# netx90_app register map
File version: 1.0
CPU: CM4 r0p1, little endian, MPU, FPU, 4 interrupt priority bits, 78 interrupts
Registers are 32-bit, read-write, reset 0x0 unless marked. A register's access mark holds for its fields unless they carry their own. Offsets are from the block's base; [hi:lo] are bit positions; {n}, {i} and the like mark numbered series; 'fields as' and 'values as' point back to an identical list.

## timer_app
Base 0xFF801600
Same registers: timer_xpic_app 0xFF900100
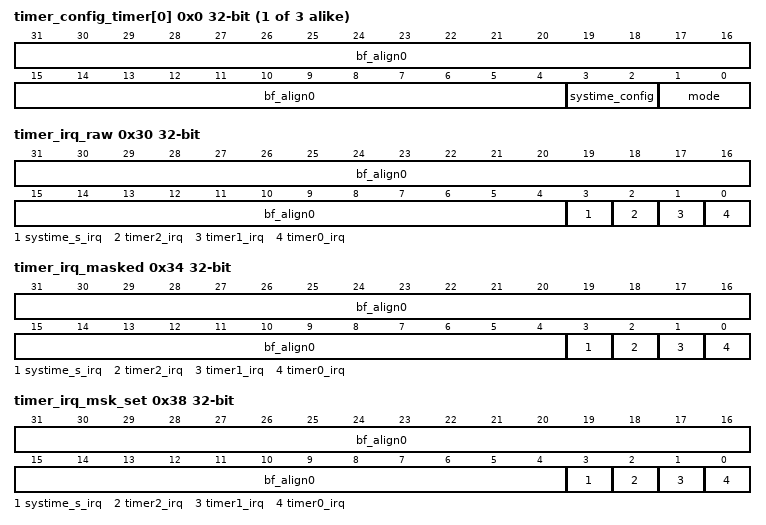
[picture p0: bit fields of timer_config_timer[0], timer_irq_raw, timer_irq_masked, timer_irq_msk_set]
{0x0+4i} timer_config_timer[{i}] (i=0..2) (reset mask 0xF) — ARM TIMER Config register0
  [31:4] bf_align0 — bitField alignment value for aeabi compatibility
  [3:2] systime_config — systime for timer (2'b00.. systime_com, 2'b01.. systime_com_uc, 2'b10.. systime_app)
  [1:0] mode — Timer0 2'b00 : Timer stops at 0 2'b01 : Timer is preload with value from preload register at 0 2'b10 : Timer (value) compare with systime (once) 2'b11 : reserved
{0xC+4i} timer_preload_timer[{i}] (i=0..2) — ARM TIMER Timer 0
  [31:0] val — preload value
{0x18+4i} timer_timer[{i}] (i=0..2) — ARM TIMER Timer 0
  [31:0] val — actual value of timer / systime compare value
0x24 timer_systime_s ro — ARM_TIMER upper SYSTIME register To allow consistent values of systime_s and systime_ns, lower bits of systime is latched to systime_ns, when systime_s is read. This register should be dedicated to accesses via ARM. xPIC software should access systime via xpic_timer_systime_s. Host software should access systime via DPM at systime_s.
  [31:0] val — Systime high: Sample systime_ns at read access to systime_s. Value is incremented, if systime_ns reaches systime_border.
0x28 timer_systime_ns ro — ARM_TIMER lower SYSTIME register To allow consistent values of systime_s and systime_ns, lower bits of systime is latched to systime_ns, when systime_s is read. If no systime_s is read before (e.g. at 2nd read access of systime_ns), the actual value of systime_ns is read. This register should be dedicated to accesses via ARM. xPIC software should access systime via xpic_timer_systime_ns. Host software should access systime via DPM at systime_ns.
  [31:0] val — Systime low: Sample systime_ns at read access to systime_s. Without sample read systime_s, read the actual value of systime_ns.
0x2C timer_compare_systime_s_value — SYSTIME sec compare value
  [31:0] val — Compare value with systime_s (seconds): Systime_s_compare_irq is set, if systime_s matches.
0x30 timer_irq_raw (reset mask 0xF) — ARM_TIMER Raw IRQ register: Read access shows status of unmasked IRQs. IRQs are set automatically and reset by writing to this register: Write access with '1' resets the appropriate IRQ. Write access with '0' does not influence this bit.
  [31:4] bf_align0 — bitField alignment value for aeabi compatibility
  [3] systime_s_irq — Systime sec Interrupt
  [2] timer2_irq — Timer 2 Interrupt
  [1] timer1_irq — Timer 1 Interrupt
  [0] timer0_irq — Timer 0 Interrupt
0x34 timer_irq_masked ro (reset mask 0xF) — ARM_TIMER Masked IRQ register: Shows status of masked IRQs (as connected to ARM/xPIC)
  fields as timer_irq_raw
0x38 timer_irq_msk_set (reset mask 0xF) — ARM_TIMER interrupt mask set: The IRQ mask enables interrupt requests for corresponding interrupt sources. As its bits might be changed by different software tasks, the IRQ mask register is not writable directly, but by set and reset masks: Write access with '1' sets interrupt mask bit (enables interrupt request for corresponding interrupt source). Write access with '0' does not influence this bit. Read access shows actual interrupt mask. Attention: Before activating interrupt mask, delete old pending interrupts by writing the same value to arm_timer_irq_raw.
  fields as timer_irq_raw
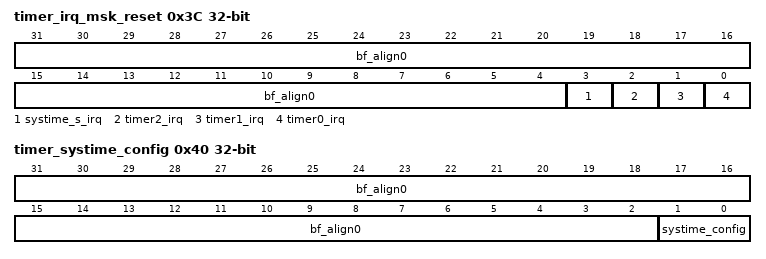
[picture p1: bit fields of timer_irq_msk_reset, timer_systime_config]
0x3C timer_irq_msk_reset (reset mask 0xF) — ARM_TIMER interrupt mask reset: This is the corresponding reset mask to disable interrupt requests for corresponding interrupt sources: Write access with '1' resets interrupt mask bit (disables interrupt request for corresponding interrupt source). Write access with '0' does not influence this bit. Read access shows actual interrupt mask.
  fields as timer_irq_raw
0x40 timer_systime_config (reset mask 0x3) — Select systime for arm_timer_systime_(ns)s functions
  [31:2] bf_align0 — bitField alignment value for aeabi compatibility
  [1:0] systime_config — systime for timer (2'b00.. systime_com, 2'b01.. systime_com_uc, 2'b10.. systime_app)
